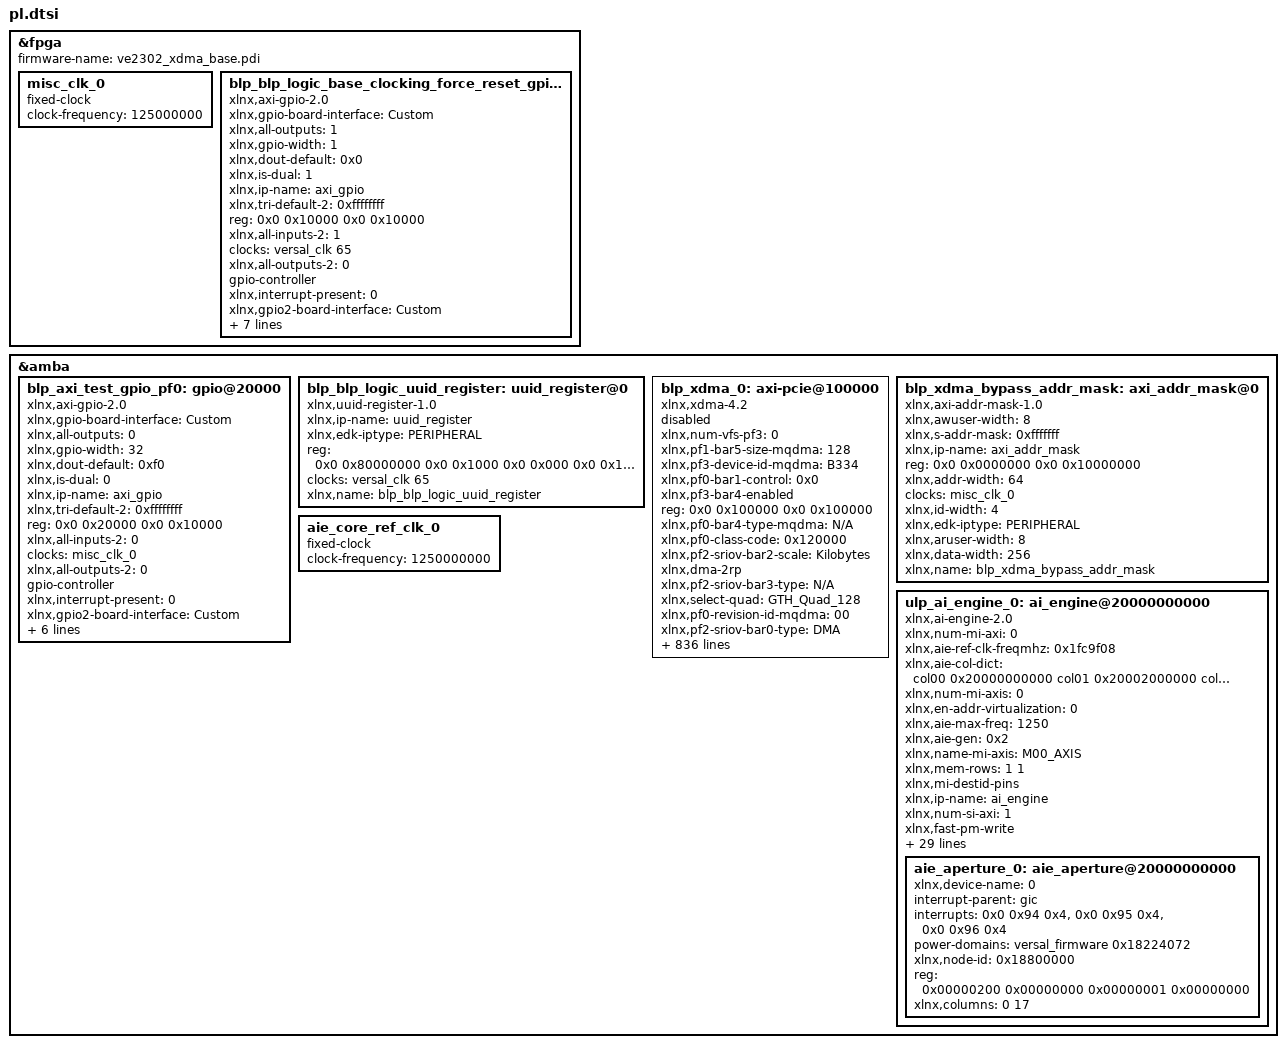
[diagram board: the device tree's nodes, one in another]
/dts-v1/;
/plugin/;
&fpga {
	firmware-name = "ve2302_xdma_base.pdi";
	misc_clk_0: misc_clk_0 {
		compatible = "fixed-clock";
		clock-frequency = <125000000>;
		#clock-cells = <0>;
	};
	blp_blp_logic_base_clocking_force_reset_gpio: gpio@10000 {
		xlnx,gpio-board-interface = "Custom";
		compatible = "xlnx,axi-gpio-2.0" , "xlnx,xps-gpio-1.00.a";
		xlnx,all-outputs = <1>;
		#gpio-cells = <2>;
		xlnx,gpio-width = <1>;
		xlnx,dout-default = <0x0>;
		xlnx,is-dual = <1>;
		xlnx,ip-name = "axi_gpio";
		xlnx,tri-default-2 = <0xffffffff>;
		reg = <0x0 0x10000 0x0 0x10000>;
		xlnx,all-inputs-2 = <1>;
		clocks = <&versal_clk 65>;
		xlnx,all-outputs-2 = <0>;
		gpio-controller;
		xlnx,interrupt-present = <0>;
		xlnx,gpio2-board-interface = "Custom";
		xlnx,edk-iptype = "PERIPHERAL";
		xlnx,dout-default-2 = <0x0>;
		xlnx,gpio2-width = <1>;
		clock-names = "s_axi_aclk";
		xlnx,tri-default = <0xffffffff>;
		xlnx,name = "blp_blp_logic_base_clocking_force_reset_gpio";
		xlnx,all-inputs = <0>;
	};
};

&amba {
	blp_axi_test_gpio_pf0: gpio@20000 {
		xlnx,gpio-board-interface = "Custom";
		compatible = "xlnx,axi-gpio-2.0" , "xlnx,xps-gpio-1.00.a";
		xlnx,all-outputs = <0>;
		#gpio-cells = <2>;
		xlnx,gpio-width = <32>;
		xlnx,dout-default = <0xf0>;
		xlnx,is-dual = <0>;
		xlnx,ip-name = "axi_gpio";
		xlnx,tri-default-2 = <0xffffffff>;
		reg = <0x0 0x20000 0x0 0x10000>;
		xlnx,all-inputs-2 = <0>;
		clocks = <&misc_clk_0>;
		xlnx,all-outputs-2 = <0>;
		gpio-controller;
		xlnx,interrupt-present = <0>;
		xlnx,gpio2-board-interface = "Custom";
		xlnx,edk-iptype = "PERIPHERAL";
		xlnx,dout-default-2 = <0x0>;
		xlnx,gpio2-width = <32>;
		clock-names = "s_axi_aclk";
		xlnx,tri-default = <0xffffffff>;
		xlnx,name = "blp_axi_test_gpio_pf0";
		xlnx,all-inputs = <0>;
	};
	blp_blp_logic_uuid_register: uuid_register@0 {
		compatible = "xlnx,uuid-register-1.0";
		clock-names = "S_AXI_ACLK";
		xlnx,ip-name = "uuid_register";
		xlnx,edk-iptype = "PERIPHERAL";
		reg = <0x0 0x80000000 0x0 0x1000 0x0 0x000 0x0 0x1000>;
		clocks = <&versal_clk 65>;
		xlnx,name = "blp_blp_logic_uuid_register";
	};
	blp_xdma_0: axi-pcie@100000 {
		xlnx,num-vfs-pf3 = <0>;
		xlnx,pf1-bar5-size-mqdma = <128>;
		xlnx,pf3-device-id-mqdma = "B334";
		xlnx,pf0-bar1-control = <0x0>;
		xlnx,pf3-bar4-enabled;
		reg = <0x0 0x100000 0x0 0x100000>;
		xlnx,pf0-bar4-type-mqdma = "N/A";
		xlnx,pf0-class-code = <0x120000>;
		xlnx,pf2-sriov-bar2-scale = "Kilobytes";
		xlnx,dma-2rp;
		xlnx,pf2-sriov-bar3-type = "N/A";
		xlnx,select-quad = "GTH_Quad_128";
		xlnx,pf0-revision-id-mqdma = <00>;
		xlnx,pf2-sriov-bar0-type = "DMA";
		xlnx,sys-rst-n-board-interface = "Custom";
		xlnx,ats-cap-nextptr = <0x0>;
		xlnx,coreclk-freq = <500>;
		xlnx,pf2-sriov-bar1-scale = "Kilobytes";
		xlnx,example-design-type = "RTL";
		xlnx,pf2-bar4-enabled;
		xlnx,pf0-bar3-aperture-size = <0x5>;
		xlnx,pf0-msi-cap-multimsgcap = <0>;
		xlnx,usr-irq-exdes;
		xlnx,pf0-bar5-type-mqdma = "N/A";
		xlnx,pf1-class-code = <0x120000>;
		xlnx,pf1-msix-cap-pba-offset = "00008FE0";
		xlnx,timeout-mult = <0x3>;
		xlnx,pf2-sriov-bar0-scale = "Kilobytes";
		xlnx,pf1-msix-cap-pba-bir = "BAR_3:2";
		xlnx,pf0-bar1-scale-mqdma = "Kilobytes";
		xlnx,pf1-vendor-id = <0x10ee>;
		xlnx,intx-rx-pin-en = <1>;
		xlnx,msix-impl-ext;
		clock-names = "user_clk_sd";
		xlnx,pf0-bar4-type = "Memory";
		xlnx,pf1-sriov-bar4-type = "N/A";
		xlnx,pf1-bar4-enabled;
		xlnx,pf1-bar4-size = <256>;
		xlnx,pf0-bar1-type = "Memory";
		xlnx,pf1-class-code-interface = <00>;
		xlnx,pf1-sriov-bar1-type = "N/A";
		xlnx,pf2-rbar-num = <1>;
		xlnx,rx-ssc-ppm = <0>;
		xlnx,pf1-bar1-size = <128>;
		xlnx,pf2-class-code = "058000";
		xlnx,pcie-board-interface = "Custom";
		xlnx,axil-master-64bit-en;
		xlnx,pf3-bar3-type = "Memory";
		xlnx,vdm-en;
		xlnx,ref-clk-freq = <0>;
		xlnx,pf1-msi-cap-multimsgcap = "1_vector";
		xlnx,pf3-bar0-type = "Memory";
		xlnx,axilite-master-en;
		xlnx,pf3-sriov-bar5-size = <2>;
		xlnx,pf1-sriov-first-vf-offset = <0>;
		xlnx,pf3-class-code = "058000";
		xlnx,pf3-sriov-bar2-size = <2>;
		xlnx,xdma-aperture-size = <0x9>;
		xlnx,pf0-msix-cap-table-offset-mqdma = <00000040>;
		xlnx,pf0-sriov-bar5-type = "N/A";
		xlnx,pf2-bar0-scale-mqdma = "Kilobytes";
		xlnx,num-queues = <1>;
		status = "disabled";
		xlnx,pf0-subsystem-vendor-id = <0x10ee>;
		xlnx,pcie-extended-tag;
		xlnx,pf0-sriov-func-dep-link = <0000>;
		xlnx,pf0-sriov-bar2-type = "N/A";
		xlnx,pf2-msi-cap-multimsgcap = "1_vector";
		xlnx,bar5-indicator = <0>;
		xlnx,pf3-revision-id = <0x0>;
		xlnx,pf0-class-code-sub = <00>;
		xlnx,pf1-vendor-id-mqdma = "10EE";
		xlnx,enable-jtag-dbg;
		xlnx,pf0-class-code-sub-mqdma = <80>;
		xlnx,dedicate-perst;
		xlnx,msix-int-table-en = <1>;
		xlnx,pf1-bar3-scale-mqdma = "Kilobytes";
		xlnx,pf0-base-class-menu-mqdma = "Memory_controller";
		xlnx,shared-logic = <0>;
		xlnx,split-dma;
		xlnx,pf2-sriov-bar3-size = <2>;
		xlnx,xdma-num-pcie-tag = <256>;
		xlnx,ps-type-in = "PS9";
		xlnx,pf2-bar0-enabled-mqdma;
		xlnx,pf1-subsystem-vendor-id = <0x10ee>;
		xlnx,ccix-dvsec;
		xlnx,pf1-sriov-func-dep-link = <0001>;
		xlnx,xdma-en;
		xlnx,pf0-device-id-mqdma = "B034";
		xlnx,pf2-sriov-bar0-size = <2>;
		xlnx,pf1-bar4-64bit;
		xlnx,pf3-msi-cap-multimsgcap = "1_vector";
		xlnx,pf3-revision-id-mqdma = <00>;
		xlnx,pf2-rbar-cap-bar0 = <0xfff0>;
		xlnx,axi-vip-in-exdes;
		xlnx,pf1-sriov-cap-initial-vf = <0>;
		xlnx,pf2-rbar-cap-bar1 = <0x0>;
		xlnx,pf3-bar0-size-mqdma = <128>;
		xlnx,pf2-rbar-cap-bar2 = <0x0>;
		xlnx,pf2-rbar-cap-bar3 = <0x0>;
		xlnx,pf2-rbar-cap-bar4 = <0x0>;
		xlnx,axibar-0 = <0x100000>;
		xlnx,pf2-rbar-cap-bar5 = <0x0>;
		xlnx,slave-read-64os-en = <0>;
		xlnx,axibar-1 = <0x0>;
		xlnx,xdma-pcie-64bit-en = "xdma_pcie_64bit_en";
		xlnx,axibar-2 = <0x0>;
		xlnx,axilite-master-scale = "Megabytes";
		xlnx,axibar-3 = <0x0>;
		xlnx,mcap-fpga-bitstream-version = <00000000>;
		xlnx,xdma-dsc-bypass;
		xlnx,include-baroffset-reg = <1>;
		xlnx,axibar-4 = <0x0>;
		xlnx,axibar-5 = <0x0>;
		xlnx,wr-ch1-enabled;
		xlnx,axist-bypass-aperture-size = <0x15>;
		xlnx,pf-swap;
		xlnx,pf0-subsystem-id-mqdma = <0007>;
		xlnx,pf0-vendor-id = <0x10ee>;
		xlnx,legacy-cfg-ext-if;
		xlnx,pf3-msix-cap-pba-bir-mqdma = "BAR_0";
		xlnx,pf1-bar2-64bit;
		xlnx,pf2-subsystem-vendor-id = "10EE";
		xlnx,pf3-bar1-size-mqdma = <128>;
		xlnx,pf1-class-code-base = <12>;
		xlnx,pf2-sriov-func-dep-link = <0002>;
		xlnx,pf0-bar4-size = <4>;
		xlnx,pf3-subsystem-id-mqdma = <0007>;
		xlnx,pf1-sriov-bar4-size = <2>;
		xlnx,pf2-base-class-menu = "Memory_controller";
		xlnx,pf0-bar0-64bit;
		xlnx,pf2-bar0-type-mqdma = "DMA";
		xlnx,pf3-bar2-scale-mqdma = "Kilobytes";
		xlnx,pf0-bar1-size = <4>;
		xlnx,pf1-bar4-aperture-size = <0x15>;
		xlnx,pf1-sriov-bar1-size = <2>;
		xlnx,pf2-bar3-type = "Memory";
		xlnx,pf1-msix-cap-pba-bir-mqdma = "BAR_0";
		xlnx,enable-resource-reduction;
		xlnx,cfg-mgmt-if;
		xlnx,pf3-bar3-size = <128>;
		xlnx,parity-settings = "None";
		xlnx,pf1-bar0-control = <0x6>;
		xlnx,pf2-bar0-type = "Memory";
		xlnx,pf3-bar0-size = <128>;
		xlnx,pf0-msix-cap-table-offset = "00009000";
		xlnx,rd-ch1-enabled;
		xlnx,pf3-bar2-size-mqdma = <128>;
		xlnx,pf1-bar0-64bit;
		xlnx,pf2-bar1-type-mqdma = "N/A";
		xlnx,msix-type = "HARD";
		xlnx,pf2-bar5-scale-mqdma = "Kilobytes";
		xlnx,pf0-msix-cap-table-size = "01F";
		xlnx,pf3-subsystem-vendor-id = "10EE";
		xlnx,sriov-en = <0>;
		xlnx,pf3-sriov-func-dep-link = <0003>;
		xlnx,pf2-expansion-rom-type = "N/A";
		xlnx,errc-dec-en;
		xlnx,pf0-bar0-control = <0x6>;
		xlnx,pf3-bar3-enabled;
		xlnx,pf0-sriov-bar0-enabled;
		xlnx,pf0-sriov-bar5-size = <2>;
		xlnx,pciebar2axibar-xdma = <0x0>;
		xlnx,sim-model;
		xlnx,bar-indicator = "BAR_1:0";
		xlnx,gtwiz-in-core = <1>;
		xlnx,pf0-sriov-bar2-size = <2>;
		xlnx,pf3-bar3-size-mqdma = <128>;
		xlnx,pf3-sriov-bar0-enabled;
		xlnx,pcie-blk-type = <1>;
		xlnx,pf2-bar2-type-mqdma = "N/A";
		xlnx,vu9p-board;
		xlnx,dma-en = <1>;
		xlnx,bar4-indicator = <0>;
		xlnx,ats-switch-unique-bdf = <1>;
		xlnx,pf0-msix-cap-table-bir = "BAR_1:0";
		xlnx,pf2-bar3-enabled;
		xlnx,pf3-interrupt-pin = "NONE";
		xlnx,pf1-msix-cap-table-size = "01F";
		xlnx,pf3-pciebar2axibar-0 = <0x0>;
		xlnx,pf3-pciebar2axibar-1 = <0x0>;
		xlnx,pf3-bar4-size-mqdma = <128>;
		xlnx,pf3-pciebar2axibar-2 = <0x0>;
		xlnx,pf3-pciebar2axibar-3 = <0x0>;
		xlnx,pf3-pciebar2axibar-4 = <0x0>;
		xlnx,pf0-bar2-aperture-size = <0x5>;
		xlnx,pf3-class-code-interface-mqdma = <00>;
		xlnx,pf3-pciebar2axibar-5 = <0x0>;
		xlnx,m-axib-num-write-scale = <1>;
		xlnx,pf2-bar3-type-mqdma = "N/A";
		xlnx,pf1-bar5-control = <0x0>;
		xlnx,pciebar2axibar-0 = <0x0>;
		xlnx,pciebar2axibar-1 = <0x0>;
		xlnx,pciebar2axibar-2 = <0x0>;
		xlnx,pciebar2axibar-3 = <0x0>;
		xlnx,pciebar2axibar-4 = <0x0>;
		xlnx,pf3-device-id = <0x1039>;
		xlnx,pciebar2axibar-5 = <0x0>;
		xlnx,xdma-pcie-prefetchable;
		xlnx,pciebar2axibar-6 = <0x0>;
		xlnx,pf0-bar0-size-mqdma = <128>;
		xlnx,pf3-bar5-size-mqdma = <128>;
		xlnx,xdma-axist-bypass;
		xlnx,pf1-class-code-mqdma = "058000";
		xlnx,pf1-msix-cap-pba-offset-mqdma = <00000050>;
		xlnx,xdma-rnum-rids = <32>;
		xlnx,pf3-sub-class-interface-menu-mqdma = "Other_memory_controller";
		xlnx,pf2-bar4-type-mqdma = "N/A";
		xlnx,pf0-bar5-control = <0x0>;
		xlnx,pf0-bar2-scale-mqdma = "Kilobytes";
		xlnx,en-axi-slave-if;
		xlnx,interrupt-out-width = <1>;
		xlnx,sriov-first-vf-offset = <1>;
		xlnx,slot-cap-reg = <00000040>;
		xlnx,pf0-bar5-index = <7>;
		xlnx,pf1-bar3-type = "Memory";
		xlnx,h2c-num-chnl = <2>;
		xlnx,pf2-bar3-size = <128>;
		xlnx,pf0-bar1-size-mqdma = <128>;
		xlnx,pf1-bar0-type = "Memory";
		xlnx,dma-mm = <1>;
		xlnx,pf2-bar0-size = <128>;
		xlnx,pf2-bar5-type-mqdma = "N/A";
		xlnx,pf0-class-code-interface-mqdma = <00>;
		xlnx,axi-addr-width = <64>;
		xlnx,s-axi-num-read = <32>;
		xlnx,egw-is-parent-ip = <1>;
		xlnx,pf0-bar4-index = <7>;
		xlnx,pf1-class-code-sub = <00>;
		xlnx,pf3-msix-cap-pba-offset-mqdma = <00000000>;
		xlnx,comp-timeout = <1>;
		xlnx,xdma-control = <0x5>;
		xlnx,rx-detect = <0>;
		xlnx,pf1-bar5-index = <7>;
		xlnx,pf3-sriov-first-vf-offset = <0>;
		xlnx,pf3-sub-class-interface-menu = "Other_memory_controller";
		xlnx,use-standard-interfaces;
		xlnx,pf2-expansion-rom-size = <4>;
		xlnx,pf3-sriov-bar4-type = "N/A";
		xlnx,pcie-id-if;
		xlnx,pf0-bar2-size-mqdma = <128>;
		xlnx,pf0-bar3-index = <7>;
		xlnx,pf3-sriov-bar1-type = "N/A";
		xlnx,pf2-bar1-scale-mqdma = "Kilobytes";
		xlnx,func-mode = <1>;
		xlnx,enable-pcie-debug-ports;
		xlnx,xlnx-ref-board = "EMB-PLUS-VPR-4616";
		xlnx,dma-reset-source-sel = <0>;
		xlnx,pf1-bar4-index = <7>;
		xlnx,pl-link-cap-max-link-width = <4>;
		xlnx,axsize-byte-access-en;
		xlnx,vcu118-board;
		xlnx,pf0-sriov-vf-device-id = "C034";
		xlnx,pf0-bar2-index = <7>;
		xlnx,bar3-indicator = <0>;
		xlnx,pf0-bar5-scale = "Kilobytes";
		xlnx,silicon-rev = "Pre-Production";
		xlnx,soft-reset-en;
		xlnx,pf2-bar5-index = <7>;
		xlnx,xdma-wnum-rids = <16>;
		xlnx,usrint-expn;
		xlnx,pf0-bar3-size-mqdma = <128>;
		xlnx,wr-ch0-enabled;
		xlnx,pf1-bar3-index = <7>;
		xlnx,pf3-sriov-vf-device-id = "C334";
		xlnx,pf1-sriov-bar5-scale = "Kilobytes";
		xlnx,pf0-bar1-index = <7>;
		xlnx,pf1-rbar-cap-bar0 = <0xfff0>;
		xlnx,pf1-bar4-scale-mqdma = "Kilobytes";
		xlnx,pf1-rbar-cap-bar1 = <0x0>;
		xlnx,pl-upstream-facing;
		xlnx,pf1-rbar-cap-bar2 = <0x0>;
		xlnx,pf0-bar4-scale = "Kilobytes";
		xlnx,pf1-rbar-cap-bar3 = <0x0>;
		xlnx,pf1-rbar-cap-bar4 = <0x0>;
		xlnx,pf2-base-class-menu-mqdma = "Memory_controller";
		xlnx,pf1-rbar-cap-bar5 = <0x0>;
		xlnx,pf2-bar4-index = <7>;
		xlnx,dma-st = <0>;
		xlnx,pf2-sriov-bar5-type = "N/A";
		xlnx,pf1-bar2-index = <7>;
		xlnx,pf2-class-code-interface = <00>;
		xlnx,tl-pf-enable-reg = <1>;
		xlnx,pf1-sriov-bar4-scale = "Kilobytes";
		xlnx,pf1-bar5-scale = "Kilobytes";
		xlnx,pf2-sriov-bar2-type = "N/A";
		xlnx,pf0-bar0-index = <0>;
		xlnx,pf3-bar5-index = <7>;
		xlnx,xdma-axi-intf-mm = <1>;
		xlnx,enable-code = <0000>;
		xlnx,axisten-freq = <125>;
		xlnx,rq-seq-num-ignore = <0>;
		xlnx,pf0-bar3-scale = "Kilobytes";
		xlnx,pf0-bar4-size-mqdma = <128>;
		xlnx,pf2-bar3-index = <7>;
		xlnx,pf2-sub-class-interface-menu = "Other_memory_controller";
		xlnx,aspm-support = "No_ASPM";
		xlnx,edk-iptype = "PERIPHERAL";
		xlnx,cfg-space-enable;
		xlnx,gen4-eieos-0s7;
		xlnx,pf1-bar1-index = <7>;
		xlnx,pf2-device-id = <0x1040>;
		xlnx,vendor-id = "10EE";
		xlnx,gt-available = "GTYP_QUAD_X0Y0,GTYP_QUAD_X0Y1";
		xlnx,axilite-master-size = <16>;
		xlnx,pf1-sriov-bar3-scale = "Kilobytes";
		xlnx,pf1-bar4-scale = "Megabytes";
		xlnx,pf3-vendor-id-mqdma = "10EE";
		xlnx,pf0-subsystem-vendor-id-mqdma = "10EE";
		xlnx,pf3-bar4-index = <7>;
		xlnx,rd-ch0-enabled;
		xlnx,pf0-bar2-scale = "Kilobytes";
		xlnx,pf1-bar3-aperture-size = <0xa>;
		xlnx,pf2-bar2-index = <7>;
		xlnx,pf1-sriov-supported-page-size = <00000553>;
		xlnx,pf2-bar5-scale = "Kilobytes";
		xlnx,pf3-msix-cap-table-bir-mqdma = "BAR_0";
		xlnx,pf3-sriov-cap-ver = <1>;
		xlnx,pf1-bar0-index = <0>;
		xlnx,pf1-sriov-bar2-scale = "Kilobytes";
		xlnx,pf1-bar3-scale = "Kilobytes";
		xlnx,pf0-bar5-size-mqdma = <128>;
		xlnx,pf3-rbar-num = <1>;
		xlnx,pf3-bar3-index = <7>;
		xlnx,pf2-device-id-mqdma = <0007>;
		xlnx,pf3-bar2-enabled;
		xlnx,pf0-bar1-scale = "Kilobytes";
		xlnx,pf1-class-code-base-mqdma = <05>;
		xlnx,pf2-bar1-index = <7>;
		xlnx,pf3-bar3-scale-mqdma = "Kilobytes";
		xlnx,pf0-bar3-type = "Memory";
		xlnx,pf1-sriov-bar3-type = "N/A";
		xlnx,pf2-bar4-scale = "Kilobytes";
		xlnx,pf1-bar3-size = <128>;
		xlnx,xdma-non-incremental-exdes;
		xlnx,type1-prefetchable-membase-memlimit = "Disabled";
		xlnx,axilite-master-control = <0x5>;
		xlnx,pf0-bar0-type = "Memory";
		xlnx,pf1-sriov-bar1-scale = "Kilobytes";
		xlnx,pf3-bar5-type = "Memory";
		xlnx,versal-part-type = "HXX";
		xlnx,pf1-bar2-scale = "Kilobytes";
		xlnx,pf1-sriov-bar0-type = "DMA";
		xlnx,en-wchnl-0;
		xlnx,pf1-bar0-size = <16>;
		xlnx,enable-auto-rxeq;
		xlnx,en-wchnl-1;
		xlnx,cfg-ext-if;
		compatible = "xlnx,xdma-4.2" , "xlnx,xdma-host-3.00";
		xlnx,pf3-bar2-index = <7>;
		xlnx,en-wchnl-2;
		xlnx,en-wchnl-3;
		xlnx,pf3-bar2-type = "Memory";
		xlnx,en-wchnl-4;
		xlnx,pf0-bar0-scale = "Megabytes";
		xlnx,pf3-bar5-scale = "Kilobytes";
		xlnx,en-wchnl-5;
		xlnx,pf2-subsystem-vendor-id-mqdma = "10EE";
		xlnx,en-wchnl-6;
		xlnx,pf2-bar0-index = <0>;
		xlnx,en-wchnl-7;
		xlnx,pf2-bar3-scale = "Kilobytes";
		xlnx,pf2-bar2-enabled;
		xlnx,axist-bypass-scale = "Megabytes";
		xlnx,pf1-class-code-sub-mqdma = <80>;
		xlnx,pf1-sriov-bar0-scale = "Kilobytes";
		xlnx,pf3-sriov-supported-page-size = <00000553>;
		xlnx,pf0-msix-cap-pba-bir = "BAR_1:0";
		xlnx,pf1-bar1-scale = "Kilobytes";
		xlnx,flr-enable;
		xlnx,pf1-sub-class-interface-menu = "Other_memory_controller";
		xlnx,pf3-bar1-index = <7>;
		xlnx,multq-en = <0>;
		xlnx,pf3-bar4-scale = "Kilobytes";
		xlnx,pf3-class-code-base = <05>;
		xlnx,pf0-rbar-num = <1>;
		xlnx,pf3-sriov-bar4-size = <2>;
		xlnx,pf2-bar2-scale = "Kilobytes";
		xlnx,pipe-debug-en;
		xlnx,pf3-sriov-bar1-size = <2>;
		xlnx,pf1-bar0-scale = "Megabytes";
		xlnx,pf2-interrupt-pin = "NONE";
		xlnx,pf3-bar0-index = <0>;
		xlnx,pf2-sriov-cap-initial-vf = <0>;
		xlnx,smmu-en = <0>;
		xlnx,m-axi-num-read = <8>;
		xlnx,pf0-msix-tar-id = <0x8>;
		xlnx,pf0-sriov-bar4-type = "N/A";
		xlnx,pf1-bar2-enabled;
		xlnx,pf1-bar4-control = <0x7>;
		xlnx,pf2-msix-cap-table-bir-mqdma = "BAR_0";
		xlnx,pf2-revision-id-mqdma = <00>;
		xlnx,pf3-bar3-scale = "Kilobytes";
		xlnx,metering-on = <1>;
		xlnx,axis-pipe-line-stage = <0>;
		xlnx,xdma-axilite-master;
		xlnx,pf0-sriov-bar1-type = "N/A";
		xlnx,pf1-msix-cap-table-size-mqdma = <001>;
		xlnx,pf2-bar1-scale = "Kilobytes";
		xlnx,bar2-indicator = <0>;
		xlnx,pf0-bar1-aperture-size = <0x5>;
		xlnx,pf3-bar2-scale = "Kilobytes";
		xlnx,pf0-expansion-rom-enable;
		xlnx,pf2-bar0-scale = "Kilobytes";
		xlnx,enable-gen4;
		xlnx,pf0-bar4-control = <0x0>;
		xlnx,pf0-revision-id = <0x0>;
		xlnx,pf0-bar0-enabled-mqdma;
		xlnx,pf2-sriov-bar5-size = <2>;
		xlnx,pf2-sub-class-interface-menu-mqdma = "Other_memory_controller";
		xlnx,s-axi-id-width = <4>;
		xlnx,msix-enabled;
		xlnx,pf3-bar1-scale = "Kilobytes";
		xlnx,pf1-bar0-scale-mqdma = "Kilobytes";
		xlnx,pf2-sriov-bar2-size = <2>;
		xlnx,pf0-sub-class-interface-menu = "Other_memory_controller";
		xlnx,pf3-bar0-enabled-mqdma;
		xlnx,pf3-msix-cap-table-size-mqdma = <000>;
		xlnx,enable-ccix;
		xlnx,last-core-cap-addr = <0x100>;
		xlnx,en-rchnl-0;
		xlnx,split-dma-single-pf;
		xlnx,en-rchnl-1;
		xlnx,en-rchnl-2;
		xlnx,mult-pf-des;
		xlnx,pf1-device-id = <0x5711>;
		xlnx,en-rchnl-3;
		xlnx,pll-type = <2>;
		xlnx,en-rchnl-4;
		xlnx,timeout0-sel = <0xe>;
		xlnx,pf0-sriov-first-vf-offset = <0>;
		xlnx,pf3-bar0-scale = "Kilobytes";
		xlnx,enable-ltssm-dbg;
		xlnx,en-rchnl-5;
		xlnx,lane-order = "Bottom";
		xlnx,en-rchnl-6;
		xlnx,pf2-class-code-sub = <80>;
		xlnx,en-rchnl-7;
		xlnx,barlite-ext-pf0 = <0x1>;
		xlnx,barlite-ext-pf1 = <0x3f>;
		xlnx,barlite-ext-pf2 = <0x0>;
		xlnx,barlite-ext-pf3 = <0x0>;
		xlnx,pf1-msix-cap-table-bir-mqdma = "BAR_0";
		xlnx,pf0-bar3-scale-mqdma = "Kilobytes";
		xlnx,enable-error-injection;
		xlnx,pf0-vendor-id-mqdma = "10EE";
		xlnx,gt-selected = "GTYP_QUAD_X0Y0";
		xlnx,ctrl-skip-mask;
		xlnx,pf1-subsystem-id-mqdma = <0007>;
		xlnx,msi-rx-pin-en = <0>;
		xlnx,pf0-bar3-size = <4>;
		xlnx,pf1-sriov-bar3-size = <2>;
		xlnx,pf2-bar5-type = "Memory";
		xlnx,pf0-bar0-size = <16>;
		xlnx,pf3-bar5-size = <128>;
		xlnx,mcap-enablement = "NONE";
		xlnx,pf1-sriov-bar0-size = <2>;
		xlnx,pf2-bar2-type = "Memory";
		xlnx,vf-barlite-ext-pf0 = <0x0>;
		xlnx,pf3-bar2-size = <128>;
		xlnx,vf-barlite-ext-pf1 = <0x0>;
		xlnx,vf-barlite-ext-pf2 = <0x0>;
		xlnx,pf2-bar0-size-mqdma = <128>;
		xlnx,vf-barlite-ext-pf3 = <0x0>;
		xlnx,pf0-msix-enabled-mqdma;
		xlnx,msi-x-options = "MSI-X_External";
		xlnx,msix-rx-decode-en;
		xlnx,pf0-expansion-rom-type = "N/A";
		xlnx,copy-sriov-pf0;
		xlnx,rx-ppm-offset = <0>;
		xlnx,pf3-class-code-mqdma = "058000";
		xlnx,axibar-highaddr-0 = <0x1fffff>;
		xlnx,versal;
		xlnx,axibar-highaddr-1 = <0x0>;
		xlnx,pf3-expansion-rom-type = "N/A";
		xlnx,axibar-highaddr-2 = <0x0>;
		xlnx,pf2-bar2-scale-mqdma = "Kilobytes";
		xlnx,axibar-highaddr-3 = <0x0>;
		xlnx,axibar-highaddr-4 = <0x0>;
		xlnx,pf2-bar1-size-mqdma = <128>;
		xlnx,name = "blp_xdma_0";
		xlnx,axibar-highaddr-5 = <0x0>;
		xlnx,pf0-class-code-base = <12>;
		xlnx,pf0-msix-cap-table-bir-mqdma = "BAR_0";
		xlnx,pf1-sriov-bar0-enabled;
		xlnx,pf0-sriov-bar4-size = <2>;
		xlnx,pf1-base-class-menu = "Memory_controller";
		xlnx,pf0-rbar-cap-bar0 = <0xfff0>;
		xlnx,pf1-bar0-type-mqdma = "DMA";
		xlnx,h2c-xdma-chnl = <0xf>;
		xlnx,pf0-rbar-cap-bar1 = <0x0>;
		xlnx,pf0-rbar-cap-bar2 = <0x0>;
		xlnx,pf1-bar4-prefetchable;
		xlnx,bar1-indicator = <0>;
		xlnx,pf0-rbar-cap-bar3 = <0x0>;
		xlnx,pf0-rbar-cap-bar4 = <0x0>;
		xlnx,pf0-sriov-bar1-size = <2>;
		xlnx,enable-clock-delay-grp;
		xlnx,pf0-rbar-cap-bar5 = <0x0>;
		xlnx,pf0-expansion-rom-scale = "Kilobytes";
		xlnx,pf1-msix-cap-table-bir = "BAR_3:2";
		xlnx,pf1-bar5-scale-mqdma = "Kilobytes";
		xlnx,pf2-bar2-size-mqdma = <128>;
		xlnx,pf1-bar1-type-mqdma = "N/A";
		xlnx,enable-pcie-debug-axi4-st;
		xlnx,xdma-st-infinite-desc-exdes;
		xlnx,pf3-bar1-enabled;
		xlnx,parity-gen = <0>;
		xlnx,pf1-bar2-aperture-size = <0x9>;
		xlnx,user-clk-freq = <1>;
		xlnx,pf1-expansion-rom-aperture-size = <0x0>;
		xlnx,shell-bridge = <0>;
		xlnx,pf2-sriov-cap-ver = <1>;
		xlnx,pf0-device-id = <0x5710>;
		xlnx,pf1-expansion-rom-scale = "Kilobytes";
		xlnx,pf2-bar3-size-mqdma = <128>;
		xlnx,xdma-rnum-chnl = <2>;
		xlnx,all-speeds-all-sides;
		xlnx,pf1-bar2-prefetchable;
		xlnx,pf2-class-code-interface-mqdma = <00>;
		xlnx,pf1-bar2-type-mqdma = "N/A";
		xlnx,mode-selection = "Advanced";
		xlnx,pf2-bar1-enabled;
		xlnx,enable-more;
		xlnx,pf2-pciebar2axibar-0 = <0x0>;
		xlnx,pf2-pciebar2axibar-1 = <0x0>;
		xlnx,tandem-rfsoc;
		xlnx,gt-loc-num = "X99Y99";
		xlnx,pf2-pciebar2axibar-2 = <0x0>;
		xlnx,pf2-pciebar2axibar-3 = <0x0>;
		xlnx,is-board-project = <1>;
		xlnx,pf2-pciebar2axibar-4 = <0x0>;
		xlnx,pf3-sriov-bar5-scale = "Kilobytes";
		xlnx,pf2-pciebar2axibar-5 = <0x0>;
		xlnx,pf3-bar4-scale-mqdma = "Kilobytes";
		xlnx,pf3-class-code-base-mqdma = <05>;
		xlnx,pcie-pfs-supported = <0>;
		xlnx,pf2-bar4-size-mqdma = <128>;
		xlnx,pciebar2axibar-axist-bypass = <0x0>;
		xlnx,pipe-line-stage = <2>;
		xlnx,pf1-bar5-type = "Memory";
		xlnx,pf2-bar5-size = <128>;
		xlnx,axist-bypass-en;
		xlnx,pf1-bar3-type-mqdma = "N/A";
		xlnx,pf1-bar2-type = "Memory";
		xlnx,pf1-bar3-control = <0x0>;
		xlnx,pf2-expansion-rom-scale = "Kilobytes";
		xlnx,pf2-bar2-size = <128>;
		xlnx,pf3-sriov-bar4-scale = "Kilobytes";
		xlnx,pl-link-cap-max-link-speed = <4>;
		xlnx,pcie-blk-locn = <0>;
		xlnx,pf1-interrupt-pin = "NONE";
		xlnx,pf0-class-code-mqdma = "058000";
		xlnx,pf3-msix-cap-table-offset-mqdma = <00000000>;
		xlnx,enh-xdma-en;
		xlnx,pf0-bar5-aperture-size = <0x5>;
		xlnx,pf0-expansion-rom-size = <4>;
		xlnx,pf3-sriov-bar3-scale = "Kilobytes";
		xlnx,pf2-bar5-size-mqdma = <128>;
		xlnx,pf0-link-status-slot-clock-config;
		xlnx,axi-bypass-64bit-en;
		xlnx,msix-pcie-internal = <0>;
		xlnx,pf0-bar3-control = <0x0>;
		xlnx,pf1-bar4-type-mqdma = "N/A";
		xlnx,enable-ibert;
		xlnx,pf3-class-code-interface = <00>;
		xlnx,functional-mode = "DMA";
		xlnx,pf0-bar0-aperture-size = <0x11>;
		xlnx,pf3-sriov-bar3-type = "N/A";
		xlnx,disable-bram-pipeline;
		xlnx,pf3-expansion-rom-size = <4>;
		xlnx,pf3-subsystem-id = <0x7>;
		xlnx,pf3-sriov-bar0-type = "DMA";
		xlnx,pf3-sriov-bar2-scale = "Kilobytes";
		xlnx,pf1-msix-tar-id = <0x9>;
		xlnx,pf3-expansion-rom-scale = "Kilobytes";
		xlnx,gtwiz-in-core-us = <1>;
		xlnx,pf1-sub-class-interface-menu-mqdma = "Other_memory_controller";
		xlnx,bar0-indicator = <1>;
		xlnx,xdma-wnum-chnl = <2>;
		xlnx,ccix-enable;
		xlnx,pf3-class-code-sub = <80>;
		xlnx,pf1-sriov-vf-device-id = "C134";
		xlnx,pf3-sriov-bar1-scale = "Kilobytes";
		xlnx,pf1-bar5-type-mqdma = "N/A";
		xlnx,pf2-msix-cap-pba-bir-mqdma = "BAR_0";
		xlnx,pf2-subsystem-id = <0x7>;
		xlnx,pf1-revision-id = <0x0>;
		xlnx,parity-prop = <0>;
		xlnx,ultrascale;
		xlnx,pf3-sriov-bar0-scale = "Kilobytes";
		xlnx,pf0-msix-cap-pba-bir-mqdma = "BAR_0";
		xlnx,pf1-bar1-scale-mqdma = "Kilobytes";
		xlnx,pf2-sriov-bar4-type = "N/A";
		xlnx,pf2-sriov-bar1-type = "N/A";
		xlnx,old-bridge-timeout = <0>;
		xlnx,pf1-subsystem-id = <0xe>;
		xlnx,pf2-sriov-first-vf-offset = <0>;
		xlnx,en-debug-ports;
		xlnx,ext-sys-clk-bufg;
		xlnx,axilite-master-aperture-size = <0x11>;
		xlnx,ip-name = "xdma";
		xlnx,pf2-class-code-sub-mqdma = <80>;
		xlnx,bridge-burst;
		xlnx,pf0-sriov-bar5-scale = "Kilobytes";
		xlnx,pciebar2axibar-axil-master = <0x0>;
		xlnx,pf0-bar4-scale-mqdma = "Kilobytes";
		xlnx,pf0-subsystem-id = <0xe>;
		xlnx,phy-lp-txpreset = <4>;
		xlnx,pf0-sriov-bar4-scale = "Kilobytes";
		xlnx,pf3-sriov-cap-initial-vf = <0>;
		xlnx,pf0-bar5-type = "Memory";
		xlnx,pf1-sriov-bar5-type = "N/A";
		xlnx,en-axi-mm-mqdma;
		xlnx,pf1-bar5-size = <128>;
		xlnx,xdma-scale = "Kilobytes";
		xlnx,pf0-bar2-type = "Memory";
		xlnx,pf1-revision-id-mqdma = <00>;
		xlnx,pf1-sriov-bar2-type = "N/A";
		xlnx,pf1-bar2-size = <64>;
		xlnx,gtcom-in-core = <2>;
		xlnx,num-of-sc = <1>;
		xlnx,pf3-bar0-scale-mqdma = "Kilobytes";
		xlnx,pf3-bar4-type = "Memory";
		xlnx,pf0-expansion-rom-aperture-size = <0x0>;
		xlnx,pf0-sriov-bar3-scale = "Kilobytes";
		xlnx,runbit-fix;
		clocks = <&misc_clk_0>;
		xlnx,pf1-base-class-menu-mqdma = "Memory_controller";
		xlnx,pf3-bar1-type = "Memory";
		xlnx,sys-reset-polarity = <0>;
		xlnx,pf1-expansion-rom-enable;
		xlnx,pf1-rbar-num = <1>;
		xlnx,pf2-vendor-id-mqdma = "10EE";
		xlnx,pf0-msix-cap-pba-offset-mqdma = <00000050>;
		xlnx,ecc-enable = <0>;
		xlnx,pf0-sriov-bar2-scale = "Kilobytes";
		xlnx,barlite1 = <2>;
		xlnx,barlite2 = <7>;
		xlnx,xdma-sts-ports;
		xlnx,pf3-sriov-bar3-size = <2>;
		xlnx,s-axi-num-write = <8>;
		xlnx,pf2-bar3-scale-mqdma = "Kilobytes";
		xlnx,two-bypass-bar;
		xlnx,pf1-device-id-mqdma = "B134";
		xlnx,pf3-bar0-enabled;
		xlnx,pf3-sriov-bar0-size = <2>;
		xlnx,pf0-sriov-bar1-scale = "Kilobytes";
		xlnx,pf0-sriov-bar3-type = "N/A";
		xlnx,c2h-num-chnl = <2>;
		xlnx,en-gt-selection;
		xlnx,barlite-int-pf0 = <0x4>;
		xlnx,tl-credits-cd = <15>;
		xlnx,barlite-int-pf1 = <0x0>;
		xlnx,pf0-class-code-interface = <00>;
		xlnx,pf0-sriov-bar0-type = "DMA";
		xlnx,barlite-int-pf2 = <0x0>;
		xlnx,barlite-int-pf3 = <0x0>;
		xlnx,disable-user-clock-root;
		xlnx,tl-credits-ch = <15>;
		xlnx,wr-ch3-enabled;
		xlnx,pf0-sriov-bar0-scale = "Kilobytes";
		xlnx,pf0-class-code-base-mqdma = <05>;
		xlnx,pf1-bar1-aperture-size = <0xa>;
		xlnx,pf2-msix-cap-pba-offset-mqdma = <00000000>;
		xlnx,pf1-sriov-cap-ver = <1>;
		xlnx,pf2-bar0-enabled;
		xlnx,pf2-msix-cap-table-offset-mqdma = <00000000>;
		xlnx,xdma-num-usr-irq = <16>;
		xlnx,vsec-cap-addr = <0x128>;
		xlnx,plltype = "QPLL1";
		xlnx,pf2-class-code-base = <05>;
		xlnx,msix-rx-pin-en = <1>;
		xlnx,pf1-bar0-enabled-mqdma;
		xlnx,pf2-sriov-bar4-size = <2>;
		xlnx,pf3-base-class-menu = "Memory_controller";
		xlnx,pf1-msix-cap-table-offset = "00008000";
		xlnx,pf3-bar0-type-mqdma = "DMA";
		xlnx,pf2-sriov-bar1-size = <2>;
		xlnx,dsc-bypass-rd = <0>;
		xlnx,axisten-if-enable-msg-route = <0x0>;
		xlnx,pf1-msix-enabled;
		xlnx,vf-barlite-int-pf0 = <0x1>;
		xlnx,vf-barlite-int-pf1 = <0x1>;
		xlnx,vf-barlite-int-pf2 = <0x1>;
		xlnx,pf1-bar0-enabled;
		xlnx,pf1-bar2-control = <0x7>;
		xlnx,vf-barlite-int-pf3 = <0x1>;
		xlnx,vu9p-tul-ex;
		xlnx,rd-ch3-enabled;
		xlnx,parity-check = <0>;
		xlnx,pf3-bar1-type-mqdma = "N/A";
		xlnx,type1-membase-memlimit-enable = "Disabled";
		xlnx,enable-dvsec;
		xlnx,dsc-bypass-rd-out = <0000>;
		xlnx,acs-ext-cap-enable;
		xlnx,en-transceiver-status-ports;
		xlnx,pf0-msix-enabled;
		xlnx,pf0-bar0-enabled;
		xlnx,pf0-bar2-control = <0x0>;
		xlnx,pf3-bar5-enabled;
		xlnx,pf0-bar0-scale-mqdma = "Kilobytes";
		xlnx,pf3-bar5-scale-mqdma = "Kilobytes";
		xlnx,pf2-subsystem-id-mqdma = <0007>;
		xlnx,pf0-interrupt-pin = <0x0>;
		xlnx,pr-cap-nextptr = <0x0>;
		xlnx,pf0-bar5-size = <4>;
		xlnx,axist-bypass-control = <0x5>;
		xlnx,pf1-sriov-bar5-size = <2>;
		xlnx,pf0-bar4-aperture-size = <0x5>;
		xlnx,pf0-bar2-size = <4>;
		xlnx,pf1-sriov-bar2-size = <2>;
		xlnx,pf2-bar4-type = "Memory";
		xlnx,en-axi-master-if;
		xlnx,pf3-bar4-size = <128>;
		xlnx,pf3-bar2-type-mqdma = "N/A";
		xlnx,pf2-bar1-type = "Memory";
		xlnx,dsc-bypass-wr-out = <0000>;
		xlnx,pf3-bar1-size = <128>;
		xlnx,pf0-sub-class-interface-menu-mqdma = "Other_memory_controller";
		xlnx,pf0-sriov-cap-initial-vf = <0>;
		xlnx,pf2-bar5-enabled;
		xlnx,pf1-msix-enabled-mqdma;
		xlnx,dsc-bypass-wr = <0>;
		xlnx,pf1-enabled = <0>;
		xlnx,pf0-sriov-supported-page-size = <00000553>;
		xlnx,pf1-expansion-rom-type = "N/A";
		xlnx,drp-clk-sel = <0>;
		xlnx,ins-loss-profile = "Add-in_Card";
		xlnx,pf3-bar3-type-mqdma = "N/A";
		xlnx,xdma-size = <64>;
		xlnx,pf2-sriov-bar0-enabled;
		xlnx,pf0-sriov-bar3-size = <2>;
		xlnx,pf0-sriov-bar0-size = <2>;
		xlnx,timeout1-sel = <0xf>;
		xlnx,axi-aclk-loopback;
		xlnx,enable-ats-switch;
		xlnx,pf1-subsystem-vendor-id-mqdma = "10EE";
		xlnx,pf1-bar0-size-mqdma = <128>;
		xlnx,pf3-bar4-type-mqdma = "N/A";
		xlnx,pf2-sriov-supported-page-size = <00000553>;
		xlnx,pf2-revision-id = <0x0>;
		xlnx,v7-gen3;
		xlnx,pf2-class-code-mqdma = "058000";
		xlnx,gtwiz-in-core-usp = <1>;
		xlnx,pf1-bar2-scale-mqdma = "Kilobytes";
		xlnx,c2h-xdma-chnl = <0xf>;
		xlnx,axi-bypass-prefetchable;
		xlnx,pipe-sim;
		xlnx,xdma-axilite-slave;
		xlnx,pf1-bar1-size-mqdma = <128>;
		xlnx,dev-port-type = <0>;
		xlnx,msi-enabled;
		xlnx,mm-slave-en = <0>;
		xlnx,m-axi-num-readq = <2>;
		xlnx,pf0-base-class-menu = "Memory_controller";
		xlnx,pf0-bar0-type-mqdma = "DMA";
		xlnx,pf3-bar5-type-mqdma = "N/A";
		xlnx,pf0-msix-cap-table-size-mqdma = <001>;
		xlnx,pf3-subsystem-vendor-id-mqdma = "10EE";
		xlnx,ins-loss-nyq = <15>;
		xlnx,pf0-bar5-scale-mqdma = "Kilobytes";
		xlnx,sriov-active-vfs = <252>;
		xlnx,pf1-bar2-size-mqdma = <128>;
		xlnx,pf3-rbar-cap-bar0 = <0xfff0>;
		xlnx,axi-id-width = <4>;
		xlnx,pf0-dev-cap2-10b-tag-completer-supported;
		xlnx,pf3-rbar-cap-bar1 = <0x0>;
		xlnx,pf3-rbar-cap-bar2 = <0x0>;
		xlnx,firstvf-offset-pf0 = <0>;
		xlnx,core-clk-freq = <2>;
		xlnx,pf3-rbar-cap-bar3 = <0x0>;
		xlnx,firstvf-offset-pf1 = <0>;
		xlnx,axibar2pciebar-0 = <0x0>;
		xlnx,pf1-msix-cap-table-offset-mqdma = <00000040>;
		xlnx,pf3-rbar-cap-bar4 = <0x0>;
		xlnx,firstvf-offset-pf2 = <0>;
		xlnx,axibar2pciebar-1 = <0x0>;
		xlnx,pf0-bar1-type-mqdma = "N/A";
		xlnx,pf1-class-code-interface-mqdma = <00>;
		xlnx,pf3-rbar-cap-bar5 = <0x0>;
		xlnx,firstvf-offset-pf3 = <0>;
		xlnx,axibar2pciebar-2 = <0x0>;
		xlnx,axibar2pciebar-3 = <0x0>;
		xlnx,axibar2pciebar-4 = <0x0>;
		xlnx,axibar2pciebar-5 = <0x0>;
		xlnx,pf1-bar4-type = "Memory";
		xlnx,pf2-bar4-size = <128>;
		xlnx,pf3-bar1-scale-mqdma = "Kilobytes";
		xlnx,axist-bypass-size = <256>;
		xlnx,gtcom-in-core-usp = <2>;
		xlnx,pf1-bar1-type = "Memory";
		xlnx,pf2-msix-cap-table-size-mqdma = <000>;
		xlnx,disable-eq-synchronizer;
		xlnx,pf2-bar1-size = <128>;
		xlnx,pf3-base-class-menu-mqdma = "Memory_controller";
		xlnx,axi-data-width = <256>;
		xlnx,pf1-bar3-size-mqdma = <128>;
		xlnx,en-pcie-debug-ports;
		xlnx,wr-ch2-enabled;
		xlnx,pciebar-num = <6>;
		xlnx,axibar-num = <1>;
		xlnx,pf0-bar2-type-mqdma = "N/A";
		xlnx,free-run-freq = <0>;
		xlnx,pf1-pciebar2axibar-0 = <0x0>;
		xlnx,ultrascale-plus;
		xlnx,enable-pcie-debug;
		xlnx,m-axi-num-write = <8>;
		xlnx,pf1-pciebar2axibar-1 = <0x0>;
		xlnx,pf1-pciebar2axibar-2 = <0x0>;
		xlnx,pf1-bar5-aperture-size = <0xa>;
		xlnx,pf1-pciebar2axibar-3 = <0x0>;
		xlnx,pf0-msix-impl-locn = "Internal";
		xlnx,pf1-expansion-rom-size = <4>;
		xlnx,pf1-pciebar2axibar-4 = <0x0>;
		xlnx,pf2-sriov-bar5-scale = "Kilobytes";
		xlnx,pf1-pciebar2axibar-5 = <0x0>;
		xlnx,pf1-pciebar2axibar-6 = <0x0>;
		xlnx,pf3-sriov-bar5-type = "N/A";
		xlnx,pf2-bar4-scale-mqdma = "Kilobytes";
		xlnx,pf3-sriov-bar2-type = "N/A";
		xlnx,pf1-bar0-aperture-size = <0x11>;
		xlnx,ext-xvc-vsec-enable;
		xlnx,pf0-sriov-cap-ver = <1>;
		xlnx,pf1-bar4-size-mqdma = <128>;
		xlnx,pf2-sriov-bar4-scale = "Kilobytes";
		xlnx,pf0-bar3-type-mqdma = "N/A";
		xlnx,pf1-bar1-control = <0x0>;
		xlnx,pf3-class-code-sub-mqdma = <80>;
		xlnx,rbar-enable;
		xlnx,pf2-class-code-base-mqdma = <05>;
		xlnx,pf2-sriov-vf-device-id = "C234";
		xlnx,rd-ch2-enabled;
		xlnx,pf2-sriov-bar3-scale = "Kilobytes";
		xlnx,num-vfs-pf0 = <0>;
		xlnx,num-vfs-pf1 = <0>;
		xlnx,component-name = "xdma_0";
		xlnx,num-vfs-pf2 = <0>;
		xlnx,pf0-msix-cap-pba-offset = "00009FE0";
	};
	blp_xdma_bypass_addr_mask: axi_addr_mask@0 {
		compatible = "xlnx,axi-addr-mask-1.0";
		xlnx,awuser-width = <8>;
		xlnx,s-addr-mask = <0xfffffff>;
		xlnx,ip-name = "axi_addr_mask";
		reg = <0x0 0x0000000 0x0 0x10000000>;
		xlnx,addr-width = <64>;
		clocks = <&misc_clk_0>;
		xlnx,id-width = <4>;
		xlnx,edk-iptype = "PERIPHERAL";
		clock-names = "aclk";
		xlnx,aruser-width = <8>;
		xlnx,data-width = <256>;
		xlnx,name = "blp_xdma_bypass_addr_mask";
	};
	ulp_ai_engine_0: ai_engine@20000000000 {
		xlnx,num-mi-axi = <0>;
		compatible = "xlnx,ai-engine-2.0" , "xlnx,ai-engine-v2.0";
		xlnx,aie-ref-clk-freqmhz = <0x1fc9f08>;
		xlnx,aie-col-dict = "col00 0x20000000000 col01 0x20002000000 col02 0x20004000000 col03 0x20006000000 col04 0x20008000000 col05 0x2000A000000 col06 0x2000C000000 col07 0x2000E000000 col08 0x20010000000 col09 0x20012000000 col10 0x20014000000 col11 0x20016000000 col12 0x20018000000 col13 0x2001A000000 col14 0x2001C000000 col15 0x2001E000000 col16 0x20020000000";
		xlnx,num-mi-axis = <0>;
		xlnx,en-addr-virtualization = <0>;
		xlnx,aie-max-freq = <1250>;
		xlnx,aie-gen = /bits/ 8 <0x2>;
		xlnx,name-mi-axis = "M00_AXIS";
		xlnx,mem-rows = /bits/ 8 <1 1>;
		xlnx,mi-destid-pins;
		xlnx,ip-name = "ai_engine";
		#size-cells = <2>;
		xlnx,num-si-axi = <1>;
		xlnx,fast-pm-write;
		reg = <0x00000200 0x00000000 0x00000001 0x00000000>;
		clocks = <&aie_core_ref_clk_0>;
		xlnx,num-noc-axis-clks = <0>;
		ranges;
		xlnx,num-clks = <0>;
		xlnx,partition-enabled = <0>;
		#address-cells = <2>;
		xlnx,num-si-axis = <0>;
		xlnx,name-mi-axi = "M00_AXI";
		xlnx,num-column = <1>;
		xlnx,aie-core-ref-ctrl-freqmhz = <1250>;
		xlnx,clk-names = "aclk0";
		xlnx,name-si-axis = "S00_AXIS";
		xlnx,fast-dm-write;
		xlnx,edk-iptype = "PERIPHERAL";
		xlnx,selected-nsu = <0>;
		xlnx,available-nsu = "NOC_NSU128_X1Y6 0x20000000000 NOC_NSU128_X2Y6 0x20002000000 NOC_NSU128_X3Y6 0x20008000000 NOC_NSU128_X4Y6 0x2000C000000 NOC_NSU128_X5Y6 0x2000E000000 NOC_NSU128_X6Y6 0x20014000000";
		clock-names = "aclk0";
		power-domains = <&versal_firmware 0x18224072>;
		xlnx,num-trig-in = <0>;
		xlnx,nsu-dict = "NOC_NSU128_X1Y6 0x20000000000 NOC_NSU128_X2Y6 0x20002000000 NOC_NSU128_X3Y6 0x20008000000 NOC_NSU128_X4Y6 0x2000C000000 NOC_NSU128_X5Y6 0x2000E000000 NOC_NSU128_X6Y6 0x20014000000";
		xlnx,en-ext-rst = <0>;
		xlnx,num-trig-out = <0>;
		xlnx,core-rows = /bits/ 8 <2 2>;
		xlnx,shim-rows = /bits/ 8 <0 1>;
		xlnx,name-si-axi = "S00_AXI";
		xlnx,start-column = <0>;
		xlnx,name = "ulp_ai_engine_0";
		xlnx,aie-site = "AIE_ML";
		aie_aperture_0: aie_aperture@20000000000 {
			xlnx,device-name = <0>;
			interrupt-parent = <&gic>;
			interrupts = <0x0 0x94 0x4>, <0x0 0x95 0x4>, <0x0 0x96 0x4>;
			#address-cells = <2>;
			power-domains = <&versal_firmware 0x18224072>;
			xlnx,node-id = <0x18800000>;
			#size-cells = <2>;
			interrupt-names = "interrupt1" , "interrupt2" , "interrupt3";
			reg = <0x00000200 0x00000000 0x00000001 0x00000000>;
			xlnx,columns = < 0 17 >;
		};
	};
	aie_core_ref_clk_0: aie_core_ref_clk_0 {
		compatible = "fixed-clock";
		clock-frequency = <1250000000>;
		#clock-cells = <0>;
	};
};
